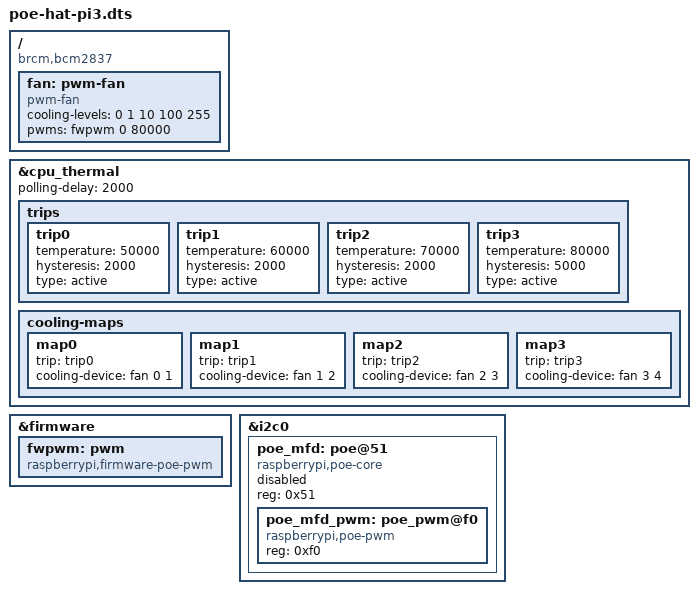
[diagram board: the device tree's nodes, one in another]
/*
* Overlay for the Raspberry Pi POE HAT.
*/
/dts-v1/;
/plugin/;

/ {
  compatible = "brcm,bcm2837";

  fragment@0 {
    target-path = "/";
    __overlay__ {
      fan: pwm-fan {
        compatible = "pwm-fan";
        cooling-levels = <0 1 10 100 255>;
        #cooling-cells = <2>;
        pwms = <&fwpwm 0 80000>;
      };
    };
  };

  fragment@1 {
    target = <&cpu_thermal>;
    __overlay__ {
      polling-delay = <2000>; /* milliseconds */
      trips {
        trip0: trip0 {
          temperature = <50000>;
          hysteresis = <2000>;
          type = "active";
        };
        trip1: trip1 {
          temperature = <60000>;
          hysteresis = <2000>;
          type = "active";
        };
        trip2: trip2 {
          temperature = <70000>;
          hysteresis = <2000>;
          type = "active";
        };
        trip3: trip3 {
          temperature = <80000>;
          hysteresis = <5000>;
          type = "active";
        };
      };
      cooling-maps {
        map0 {
          trip = <&trip0>;
          cooling-device = <&fan 0 1>;
        };
        map1 {
          trip = <&trip1>;
          cooling-device = <&fan 1 2>;
        };
        map2 {
          trip = <&trip2>;
          cooling-device = <&fan 2 3>;
        };
        map3 {
          trip = <&trip3>;
          cooling-device = <&fan 3 4>;
        };
      };
    };
  };

  fragment@2 {
    target = <&firmware>;
    __overlay__ {
      fwpwm: pwm {
        compatible = "raspberrypi,firmware-poe-pwm";
        #pwm-cells = <2>;
      };
    };
  };

  fragment@3 {
    target = <&i2c0>;
    i2c_bus: __overlay__ {
      #address-cells = <1>;
      #size-cells = <0>;

      poe_mfd: poe@51 {
        compatible = "raspberrypi,poe-core";
        reg = <0x51>;
        status = "disabled";

        poe_mfd_pwm: poe_pwm@f0 {
          compatible = "raspberrypi,poe-pwm";
          reg = <0xf0>;
          status = "okay";
          #pwm-cells = <2>;
        };
      };
    };
  };
};
